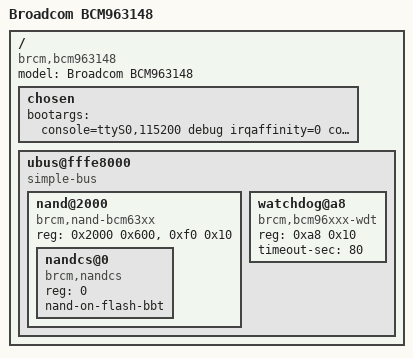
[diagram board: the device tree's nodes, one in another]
/*
 * Broadcom BCM63148 Reference Board DTS
 */

#include "bcm_963xx_template.dtsi"

/ {
	compatible = "brcm,bcm963148";
	model = "Broadcom BCM963148";

	/* increase coherent_pool size for ARM-based chip */
	chosen {
		bootargs = "console=ttyS0,115200 debug irqaffinity=0 coherent_pool=1M";
	};

	/* Legacy UBUS base */
	ubus@fffe8000 {
		compatible = "simple-bus";
		#address-cells = <1>;
		#size-cells = <1>;
		ranges = <0 0xfffe8000 0x8000>;

		nand@2000 {
			#address-cells = <1>;
			#size-cells = <0>;
			compatible = "brcm,nand-bcm63xx", "brcm,brcmnand-v7.1";
			reg = <0x2000 0x600>, <0xf0 0x10>;
			reg-names = "nand", "nand-int-base";
			status = "okay";

			nandcs@0 {
				compatible = "brcm,nandcs";
				reg = <0>;
				nand-on-flash-bbt;
			};

		};

		watchdog@a8 {
			compatible = "brcm,bcm96xxx-wdt";
			reg = <0xa8 0x10>;
			timeout-sec = <80>;
		};
	};
};
